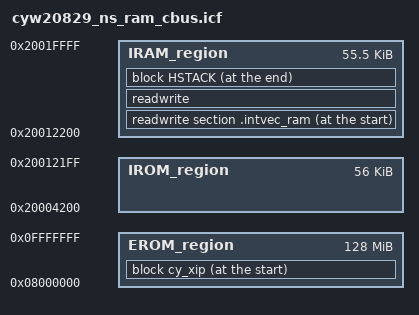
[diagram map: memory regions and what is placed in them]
/*******************************************************************************
* \file cyw20829_ns_ram_cbus.icf
* \version 1.0.0
*
* Linker file for the IAR compiler.
*
* The main purpose of the linker script is to describe how the sections in the
* input files should be mapped into the output file, and to control the memory
* layout of the output file.
*
* \note The entry point is fixed and starts at 0x20004200. The valid application
* image should be placed there.
*
* \note The linker files included with the PDL template projects must be generic
* and handle all common use cases. Your project may not use every section
* defined in the linker files. In that case you may see warnings during the
* build process. In your project, you can simply comment out or remove the
* relevant code in the linker file.
*
********************************************************************************
* \copyright
* Copyright 2016-2021 Cypress Semiconductor Corporation
* SPDX-License-Identifier: Apache-2.0
*
* Licensed under the Apache License, Version 2.0 (the "License");
* you may not use this file except in compliance with the License.
* You may obtain a copy of the License at
*
*     http://www.apache.org/licenses/LICENSE-2.0
*
* Unless required by applicable law or agreed to in writing, software
* distributed under the License is distributed on an "AS IS" BASIS,
* WITHOUT WARRANTIES OR CONDITIONS OF ANY KIND, either express or implied.
* See the License for the specific language governing permissions and
* limitations under the License.
*******************************************************************************/

define symbol CODE_ROM_NS_CBUS_START = 0x00000000;
define symbol CODE_ROM_NS_CBUS_SIZE = 0x00010000;
define symbol CODE_SRAM0_NS_CBUS_START = 0x04004200;
define symbol CODE_SRAM0_NS_CBUS_SIZE = 0x0000E000;
define symbol CODE_XIP_NS_CBUS_START = 0x08000000;
define symbol CODE_XIP_NS_CBUS_SIZE = 0x08000000;

define symbol DATA_ROM_NS_SAHB_START = 0x00000000;
define symbol DATA_ROM_NS_SAHB_SIZE  = 0x00000000;
define symbol BSS_ROM_NS_SAHB_START = 0x00000000;
define symbol BSS_ROM_NS_SAHB_SIZE = 0x00000000;
define symbol DATA_SRAM0_NS_SAHB_START = 0x20012200;
define symbol DATA_SRAM0_NS_SAHB_SIZE  = 0x0000DE00;
define symbol BSS_SRAM0_NS_SAHB_START = 0x20000000;
define symbol BSS_SRAM0_NS_SAHB_SIZE = 0x00000000;
define symbol DATA_XIP_NS_SAHB_START = 0x60000000;
define symbol DATA_XIP_NS_SAHB_SIZE  = 0x00000000;
define symbol BSS_XIP_NS_SAHB_START = 0x60000000;
define symbol BSS_XIP_NS_SAHB_SIZE = 0x00000000;

/* Load address */
define symbol CODE_SRAM0_NS_LOAD_ADDRESS = 0x20004200;

/* The size of the stack section at the end of CM33 SRAM */
define symbol STACK_SIZE = 0x1000;
define symbol HEAP_SIZE = 0x0400;

/* The symbols below define the location and size of blocks of memory in the target.
 * Use these symbols to specify the memory regions available for allocation.
 */

/*-Sizes-*/
if (!isdefinedsymbol(__STACK_SIZE)) {
  define symbol __size_cstack__ = STACK_SIZE;
} else {
  define symbol __size_cstack__ = __STACK_SIZE;
}
define symbol __size_proc_stack__ = 0x0;

/* Defines the minimum heap size. The actual heap size will be expanded to the end of the stack region */
if (!isdefinedsymbol(__HEAP_SIZE)) {
    define symbol __size_heap__ = HEAP_SIZE;
} else {
  define symbol __size_heap__ = __HEAP_SIZE;
}

define memory mem with size = 4G;
define region IROM_region = mem:[from CODE_SRAM0_NS_LOAD_ADDRESS size CODE_SRAM0_NS_CBUS_SIZE];
define region IRAM_region = mem:[from DATA_SRAM0_NS_SAHB_START size DATA_SRAM0_NS_SAHB_SIZE];
define region EROM_region = mem:[from CODE_XIP_NS_CBUS_START size CODE_XIP_NS_CBUS_SIZE];

define block CSTACK     with alignment = 8, size = __size_cstack__     { };
define block PROC_STACK with alignment = 8, size = __size_proc_stack__ { };
define block HEAP       with expanding size, alignment = 8, minimum size = __size_heap__ { };
define block HSTACK {block HEAP, block PROC_STACK, last block CSTACK};
define block RO     {first section .intvec, readonly};

define block cy_xip { section .cy_xip };

/*-Initializations-*/
initialize by copy { readwrite };
do not initialize  { section .noinit, section .intvec_ram };

/*-Placement-*/

/* Execute in Place (XIP). See the smif driver documentation for details. */
"cy_xip" : place at start of EROM_region  { block cy_xip };

/* CODE */
place at address CODE_SRAM0_NS_LOAD_ADDRESS  { block RO };

/* RAM */
place at start of IRAM_region  { readwrite section .intvec_ram};
place in          IRAM_region  { readwrite };
place at end   of IRAM_region  { block HSTACK };

keep {  section .intvec  };
keep {  section .cy_xip  };

/* EOF */
